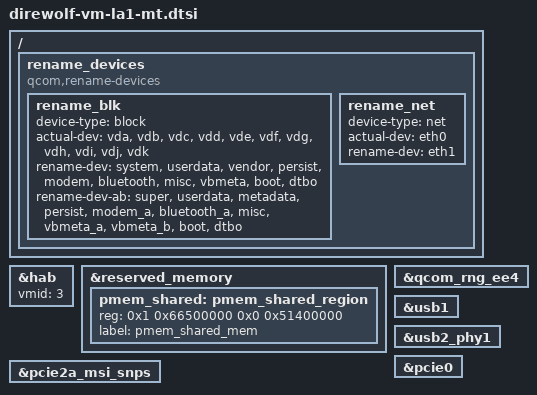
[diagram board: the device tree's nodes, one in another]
&hab {
	vmid = <3>;
};

&reserved_memory {
	pmem_shared: pmem_shared_region {
		reg = <0x1 0x66500000 0x0 0x51400000>;
		label = "pmem_shared_mem";
	};
};

/ {
	rename_devices: rename_devices {
		compatible = "qcom,rename-devices";

		rename_blk: rename_blk {
			device-type = "block";
			actual-dev = "vda", "vdb", "vdc",
					"vdd", "vde", "vdf",
					"vdg", "vdh", "vdi",
					"vdj", "vdk";
			rename-dev = "system", "userdata", "vendor",
					"persist", "modem", "bluetooth",
					"misc", "vbmeta", "boot", "dtbo";
			rename-dev-ab = "super", "userdata", "metadata",
					"persist", "modem_a", "bluetooth_a",
					"misc", "vbmeta_a", "vbmeta_b",
					"boot", "dtbo";
		};

		rename_net: rename_net {
			device-type = "net";
			actual-dev = "eth0";
			rename-dev = "eth1";
		};
	};
};

&qcom_rng_ee4 {
	status = "okay";
};

&usb1 {
	status = "okay";
};

&usb2_phy1 {
	status = "okay";
};

&pcie0 {
	status = "okay";
};

&pcie2a_msi_snps {
	status = "okay";
};
